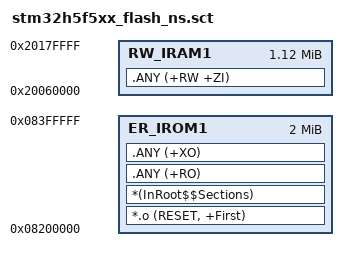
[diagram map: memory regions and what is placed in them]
; *************************************************************
; *** Scatter-Loading Description File generated by uVision ***
; *************************************************************

LR_IROM1 0x08200000 0x00200000  {    ; load region size_region
  ER_IROM1 0x08200000 0x00200000  {  ; load address = execution address
   *.o (RESET, +First)
   *(InRoot$$Sections)
   .ANY (+RO)
   .ANY (+XO)
  }
  RW_IRAM1 0x20060000 0x00120000  {  ; RW data
   .ANY (+RW +ZI)
  }
}

